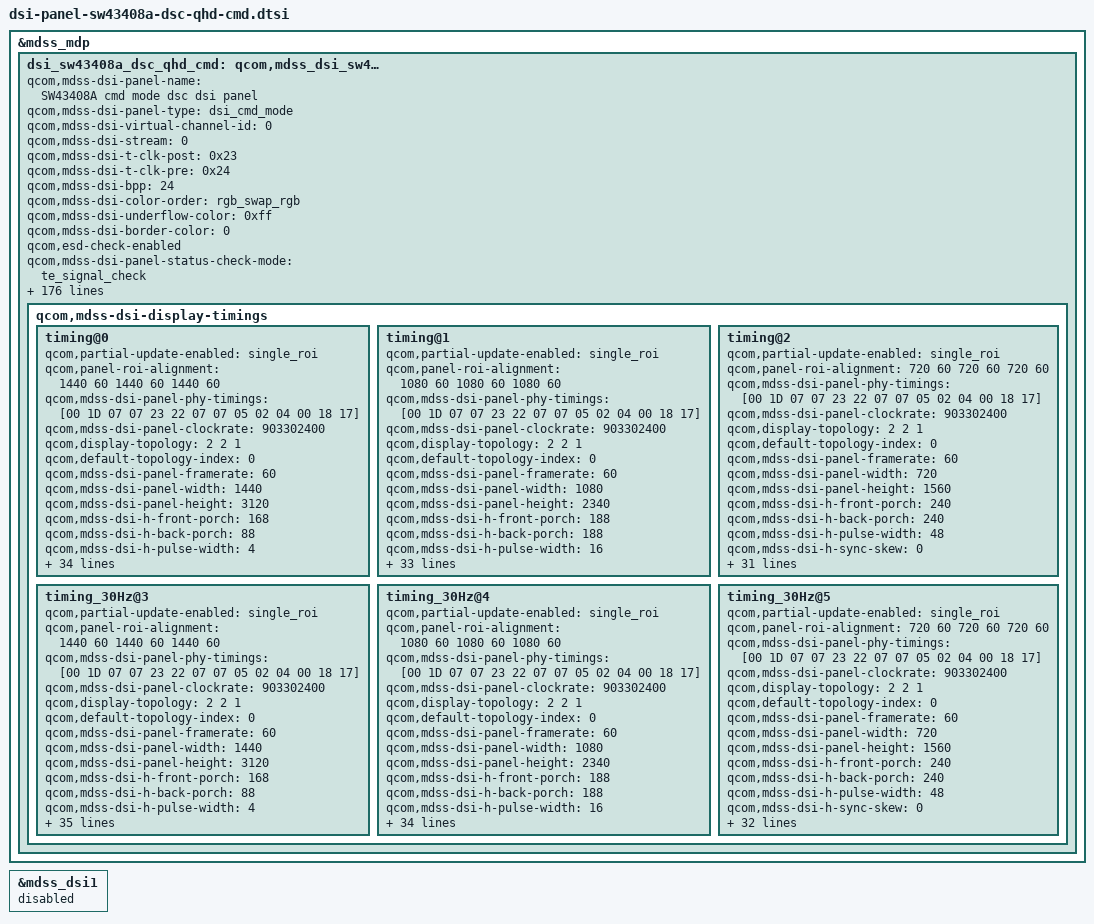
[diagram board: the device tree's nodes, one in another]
/* Copyright (c) 2014, Code Aurora Forum. All rights reserved.
 *
 * This program is free software; you can redistribute it and/or modify
 * it under the terms of the GNU General Public License version 2 and
 * only version 2 as published by the Free Software Foundation.
 *
 * This program is distributed in the hope that it will be useful,
 * but WITHOUT ANY WARRANTY; without even the implied warranty of
 * MERCHANTABILITY or FITNESS FOR A PARTICULAR PURPOSE.  See the
 * GNU General Public License for more details.
 */

&mdss_mdp {
    dsi_sw43408a_dsc_qhd_cmd: qcom,mdss_dsi_sw43408a_dsc_qhd_cmd {
        qcom,mdss-dsi-panel-name = "SW43408A cmd mode dsc dsi panel";
		qcom,mdss-dsi-panel-type = "dsi_cmd_mode";

		qcom,mdss-dsi-virtual-channel-id = <0>;
		qcom,mdss-dsi-stream = <0>;
		qcom,mdss-dsi-t-clk-post = <0x23>;
		qcom,mdss-dsi-t-clk-pre = <0x24>;
		qcom,mdss-dsi-bpp = <24>;
		qcom,mdss-dsi-color-order = "rgb_swap_rgb";
		qcom,mdss-dsi-underflow-color = <0xff>;
		qcom,mdss-dsi-border-color = <0>;
		qcom,esd-check-enabled;
		qcom,mdss-dsi-panel-status-check-mode = "te_signal_check";
		qcom,mdss-dsi-traffic-mode = "burst_mode";
		qcom,mdss-dsi-lane-map = "lane_map_0123";
		qcom,mdss-dsi-bllp-eof-power-mode;
		qcom,mdss-dsi-bllp-power-mode;
		qcom,mdss-dsi-lane-0-state;
		qcom,mdss-dsi-lane-1-state;
		qcom,mdss-dsi-lane-2-state;
		qcom,mdss-dsi-lane-3-state;
		qcom,mdss-dsi-reset-sequence = <1 10>, <0 2>, <1 10>;
		qcom,mdss-dsi-dma-trigger = "trigger_sw";
		qcom,mdss-dsi-mdp-trigger = "none";
		qcom,mdss-dsi-te-pin-select = <1>;
		qcom,mdss-dsi-wr-mem-start = <0x2c>;
		qcom,mdss-dsi-wr-mem-continue = <0x3c>;
		qcom,mdss-dsi-te-dcs-command = <1>;
		qcom,mdss-dsi-te-check-enable;
		qcom,mdss-dsi-te-using-te-pin;
		qcom,mdss-dsi-lp11-init;
		qcom,mdss-dsi-tx-eot-append;
		qcom,ulps-enabled;
		//qcom,mdss-dsi-force-clock-lane-hs = <1>;

		qcom,mdss-dsi-panel-hdr-enabled;
		qcom,mdss-dsi-panel-hdr-color-primaries = <14649 15851 33084 15473 13806 31961 7476 2719>;
		qcom,mdss-dsi-panel-peak-brightness = <5643000>;		/* max. 500nits */
		qcom,mdss-dsi-panel-blackness-level = <6134>;
		qcom,dynamic-mode-switch-enabled;
		qcom,dynamic-mode-switch-type = "dynamic-resolution-switch-immediate";
		lge,drs-mngr-enabled;
		lge,drs-mngr-internal-pps-switch-enabled;
		lge,use-ambient;
		lge,aod-interface-data = "partial", "partial", "partial";

		lge,blmap = <
			0
			1 1 2 3 4 4 5 6 6 7 7 7 7 8 8 9 10 10 11 13
			14 15 16 18 19 21 23 24 26 29 31 33 34 36 38 41 43 45 47 49
			52 54 56 58 60 63 67 71 75 79 84 88 92 97 101 106 111 115 120 123
			126 129 132 135 139 142 145 148 151 154 157 161 164 168 172 176 179 182 186 189
			193 197 201 206 209 212 216 219 222 226 229 232 235 238 241 245 248 252 255 258
			262 266 269 273 276 280 284 288 291 295 299 304 308 312 317 321 326 330 335 339
			344 348 353 358 362 367 372 377 382 388 394 400 405 410 415 420 426 431 436 441
			447 452 458 464 469 475 481 487 493 499 505 511 517 524 530 536 543 549 556 561
			566 570 575 581 586 592 597 603 608 614 619 625 630 636 641 647 653 658 663 668
			673 678 684 689 694 700 705 711 716 722 727 733 738 743 749 754 760 766 771 777
			782 787 792 797 803 808 814 820 826 831 834 837 840 843 846 849 851 854 857 860
			863 866 868 871 874 877 880 883 886 889 891 894 897 900 903 906 909 911 914 917
			920 923 926 929 932 935 938 941 944 947 951 954 957 960 964 964 964 964 964 964
			964 964 964 965 965 965 965 965 966 966 966 967 967 967 968 968 969 969 970 970
			971 972 972 973 974 974 975 977 978 979 980 982 983 985 986 987 989 991 992 993
			993 993 993 993 994 994 994 994 994 995 995 995 995 996 996 996 996 997 997 997
			997 998 998 998 999 999 999 999 1000 1000 1000 1001 1001 1001 1002 1002 1002 1003 1003 1004
			1004 1004 1005 1005 1006 1006 1006 1007 1007 1008 1008 1008 1009 1009 1010 1010 1011 1011 1012 1012
			1013 1013 1014 1014 1015
		>;
		lge,blmap-ve = <
			0
			9 9 9 9 9 9 9 9 9 9 10 12 13 15 16 18 19 20 22 23
			25 26 28 29 30 32 33 35 36 37 39 40 42 43 45 46 50 54 58 61
			65 69 73 77 81 84 88 92 96 100 104 107 111 115 119 123 127 130 134 138
			142 146 150 154 158 162 166 170 174 178 182 186 190 193 197 201 205 209 213 217
			221 226 231 236 237 242 247 251 256 261 266 270 275 280 285 290 294 299 304 309
			314 318 323 328 333 337 342 347 353 358 364 370 376 381 387 393 399 404 410 416
			422 427 433 439 444 450 456 462 467 473 479 485 490 496 502 509 515 521 528 534
			541 546 553 559 565 572 578 584 591 597 603 610 616 623 629 635 642 648 655 661
			667 674 680 686 692 698 705 711 717 723 730 736 742 748 754 761 767 773 779 785
			792 798 804 808 812 816 820 824 828 831 835 839 843 847 851 855 859 863 867 871
			874 878 882 886 890 894 898 902 905 909 913 917 920 924 928 931 935 939 943 946
			950 954 958 961 965 969 972 976 980 984 987 991 992 993 993 994 995 996 996 997
			998 999 1000 1000 1001 1002 1003 1004 1004 1005 1006 1007 1007 1008 1009 1009 1009 1009 1009 1009
			1009 1009 1009 1009 1009 1009 1009 1009 1009 1009 1009 1009 1009 1009 1009 1009 1009 1009 1009 1009
			1009 1009 1009 1009 1009 1009 1009 1009 1009 1009 1009 1009 1009 1009 1009 1009 1009 1010 1010 1010
			1010 1010 1010 1010 1010 1010 1010 1010 1010 1010 1011 1011 1011 1011 1011 1011 1011 1011 1011 1011
			1011 1011 1011 1011 1011 1011 1011 1011 1011 1011 1011 1011 1011 1011 1011 1011 1011 1011 1011 1012
			1012 1012 1012 1012 1012 1012 1012 1012 1012 1013 1013 1013 1013 1013 1013 1014 1014 1014 1014 1014
			1014 1015 1015 1015 1015
		>;
		lge,blmap-ex = <
			1
			131 131 131 131 131 131 131 131 131 147 160 175 186 196 208 218 227 234 242 251
			258 264 270 277 284 289 295 300 306 311 317 322 327 332 335 338 350 361 373 384
			393 402 410 418 426 434 442 449 456 462 468 474 480 486 492 498 503 508 513 517
			522 527 532 536 541 545 549 553 557 561 565 569 572 576 580 585 590 595 599 603
			607 612 616 620 624 629 633 637 643 648 654 658 662 667 671 675 679 682 685 688
			691 694 696 699 702 705 708 712 715 718 724 730 736 741 746 752 758 764 774 785
			790 796 801 807 813 819 826 832 838 843 848 854 859 865 865 865 865 865 865 865
			875 883 890 898 905 913 923 931 938 945 953 961 970 978 985 993 999 1006 1012 1012
			1012 1012 1012 1012 1012 1012 1012 1012 1012 1012 1012 1012 1012 1012 1012 1012 1012 1012 1012 1012
			1012 1012 1012 1012 1012 1012 1012 1012 1012 1012 1012 1012 1012 1012 1012 1012 1012 1012 1012 1012
			1012 1012 1012 1012 1012 1012 1012 1012 1012 1012 1012 1012 1012 1012 1012 1012 1012 1012 1012 1012
			1012 1012 1012 1012 1012 1012 1012 1012 1012 1012 1012 1012 1012 1012 1012 1012 1012 1012 1012 1012
			1012 1012 1012 1012 1012 1012 1012 1012 1012 1012 1012 1012 1012 1012 1012
		>;

		lge,dynamic-blmap-normal = <
			0
			7 7 7 7 7 7 7 7 7 7 8 9 10 11 12 13 13 14 15 16
			17 18 19 20 21 22 23 24 25 25 26 27 28 29 30 31 33 36 38 40
			42 45 47 49 52 54 56 58 61 63 65 67 70 72 74 77 79 81 83 86
			88 91 94 98 101 104 107 110 114 117 120 123 127 130 133 136 139 143 146 149
			152 155 159 162 165 168 171 175 178 181 184 188 191 194 197 200 204 207 210 213
			216 220 223 226 229 233 236 239 242 245 248 251 254 257 260 263 266 269 272 275
			278 281 284 287 290 293 296 299 302 305 308 311 314 317 321 325 329 334 338 342
			346 349 353 357 362 366 370 374 378 382 387 391 395 399 403 407 412 416 421 426
			431 436 442 447 452 457 462 467 472 477 483 488 493 498 503 508 513 518 524 529
			534 539 544 549 554 558 563 568 573 578 582 587 592 597 602 606 611 616 621 625
			630 635 640 645 649 654 659 664 668 673 677 682 686 691 695 700 705 709 714 718
			723 727 732 737 741 746 750 755 759 764 768 773 777 781 784 788 792 796 800 804
			807 811 815 819 823 827 830 834 838 842 846 850 853 857 861 864 868 871 875 878
			881 885 888 891 895 898 902 905 908 912 915 919 922 925 929 932 936 939 942 946
			949 952 956 959 963 966 967 968 969 971 972 973 974 975 977 980 982 984 986 989
			991 993 993 993 994 994 994 994 994 994 995 995 995 995 995 995 995 996 996 996
			996 997 997 998 998 998 999 999 999 1000 1000 1001 1001 1001 1002 1002 1003 1003 1004 1004
			1005 1005 1006 1006 1007 1007 1007 1008 1008 1009 1009 1010 1010 1010 1011 1011 1012 1012 1012 1013
			1013 1014 1014 1015 1015
		>;
		lge,dynamic-blmap-brighter = <
			0
			7 7 7 7 7 7 7 7 7 7 7 7 7 8 8 9 10 10 11 13
			14 15 16 18 19 21 23 24 26 29 31 33 34 36 38 41 43 45 47 49
			52 54 56 58 60 63 67 71 75 79 84 88 92 97 101 106 111 115 120 123
			126 129 132 135 139 142 145 148 151 154 157 161 164 168 172 176 179 182 186 189
			193 197 201 206 209 212 216 219 222 226 229 232 235 238 241 245 248 252 255 258
			262 266 269 273 276 280 284 288 291 295 299 304 308 312 317 321 326 330 335 339
			344 348 353 358 362 367 372 377 382 388 394 400 405 410 415 420 426 431 436 441
			447 452 458 464 469 475 481 487 493 499 505 511 517 524 530 536 543 549 556 561
			566 570 575 581 586 592 597 603 608 614 619 625 630 636 641 647 653 658 663 668
			673 678 684 689 694 700 705 711 716 722 727 733 738 743 749 754 760 766 771 777
			782 787 792 797 803 808 814 820 826 831 834 837 840 843 846 849 851 854 857 860
			863 866 868 871 874 877 880 883 886 889 891 894 897 900 903 906 909 911 914 917
			920 923 926 929 932 935 938 941 944 947 951 954 957 960 964 964 964 964 964 964
			964 964 964 965 965 965 965 965 966 966 966 967 967 967 968 968 969 969 970 970
			971 972 972 973 974 974 975 977 978 979 980 982 983 985 986 987 989 991 992 993
			993 993 993 993 994 994 994 994 994 995 995 995 995 996 996 996 996 997 997 997
			997 998 998 998 999 999 999 999 1000 1000 1000 1001 1001 1001 1002 1002 1002 1003 1003 1004
			1004 1004 1005 1005 1006 1006 1006 1007 1007 1008 1008 1008 1009 1009 1010 1010 1011 1011 1012 1012
			1013 1013 1014 1014 1015
		>;
		lge,blmap-hdr = <
			0
			7 7 7 7 7 7 7 7 7 7 8 10 11 12 14 15 16 18 19 20
			22 23 25 26 27 29 30 31 33 34 35 37 38 39 41 42 46 49 53 56
			60 64 67 71 74 78 82 85 89 92 96 100 103 107 110 114 118 121 125 128
			132 136 140 144 147 151 155 159 163 167 170 174 178 182 186 190 193 197 201 205
			209 213 217 221 224 228 233 237 241 245 250 254 258 262 267 271 275 279 284 288
			292 296 301 305 309 313 318 322 327 332 337 343 348 353 358 363 368 374 379 384
			389 394 399 404 410 415 420 425 430 435 441 446 451 456 462 468 474 480 487 493
			499 504 510 516 522 528 535 541 547 553 559 565 571 577 584 590 596 602 609 615
			621 627 633 639 645 651 657 663 669 675 681 687 693 699 705 711 717 723 729 735
			741 747 753 758 762 767 772 777 781 786 791 795 800 805 810 814 819 824 828 833
			838 842 847 852 857 861 866 869 872 875 878 882 885 888 891 894 897 900 903 907
			910 913 916 919 922 925 928 932 935 938 941 944 947 949 952 954 957 959 962 964
			967 969 972 974 977 979 982 984 987 989 992 994 997 999 1002 1002 1002 1002 1002 1002
			1002 1002 1002 1002 1002 1002 1002 1002 1002 1002 1003 1003 1003 1003 1003 1003 1003 1003 1003 1003
			1003 1003 1003 1003 1003 1003 1003 1003 1003 1004 1004 1004 1004 1004 1004 1004 1004 1005 1005 1005
			1005 1005 1005 1005 1005 1005 1005 1005 1005 1005 1006 1006 1006 1006 1006 1006 1006 1006 1006 1006
			1006 1006 1006 1007 1007 1007 1007 1007 1007 1008 1008 1008 1008 1008 1008 1008 1009 1009 1009 1009
			1009 1009 1010 1010 1010 1010 1010 1011 1011 1011 1011 1012 1012 1012 1012 1013 1013 1013 1013 1014
			1014 1014 1014 1015 1015
		>;

		qcom,mdss-pan-physical-width-dimension = <68>;
		qcom,mdss-pan-physical-height-dimension = <147>;

		lge,update-pps-in-lp-mode;
		lge,mdss-dsi-nolp-command = [
			15 01 00 00 00 00 02 B0 AC
			39 01 00 00 00 00 05 30 00 00 0C 2F
			39 01 00 00 00 00 05 31 00 00 05 9F
			39 01 00 00 00 00 07 55 16 29 C0 04 78 DB
			39 01 00 00 00 00 0B C3 10 15 1F 12 AD 4D B1 51 BD 1D
			39 01 00 00 00 00 08 E5 00 3A 00 36 00 3A 10
			39 01 00 00 00 00 3D E6 0F FF 00 0F FF 00 0F FF 00 0F FF 00 0F FF 00 0F FF 00 0F FF 00 0F FF 00 0F FF 00 0F FF 00 0F FF 00 0F FF 00 0F FF 00 0F FF 00 0F FF 00 0F FF 00 0F FF 00 0F FF 00 0F FF 00 0F FF 00
			39 01 00 00 00 00 1F E7 0F FF 00 0F FF 00 0F FF 00 0F FF 00 0F FF 00 0F FF 00 0F FF 00 0F FF 00 0F FF 00 0F FF 00
			15 01 00 00 00 00 02 EA 6F
			39 01 00 00 28 00 0F CB 80 5C 07 11 34 54 4F 5A 33 19 60 00 00 00
			05 01 00 00 00 00 01 13
			39 01 00 00 55 00 0D B4 2F 02 11 03 31 31 31 0A 10 92 12 00
			39 01 00 00 00 00 08 E5 00 3A 00 36 00 0F 10
			39 01 00 00 00 00 3D E6 30 00 12 30 00 12 30 00 12 30 00 12 11 B0 61 02 4D C4 02 B3 5E 02 DB 37 02 EA 27 0F FF 00 30 00 12 30 00 12 30 00 12 30 00 12 11 B0 61 02 4D C4 02 B3 5E 02 DB 37 02 EA 27 0F FF 00
			39 01 00 00 00 00 1F E7 30 00 13 30 00 13 30 00 13 38 94 AD 38 94 AD 30 00 13 30 00 13 30 00 13 38 94 AD 38 94 AD
			15 01 00 00 00 00 02 B0 CA
		];
		lge,mdss-dsi-nolp-command-state = "dsi_lp_mode";

		lge,mdss-dsi-aod-area-command = [
			15 01 00 00 00 00 02 B0 AC
			39 01 00 00 00 00 05 30 00 00 02 CF
			39 01 00 00 00 00 05 31 00 00 05 9F
		];
		lge,mdss-dsi-aod-area-command-state = "dsi_lp_mode";

		lge,mdss-dsi-lp2-command = [
			15 01 00 00 00 00 02 B0 AC
			39 01 00 00 00 00 07 55 16 29 C9 04 78 DB
			39 01 00 00 00 00 19 C2 70 8A 0A 0A 33 8C 8C 33 8C 8C 0A ED AD 63 23 00 00 64 24 43 60 15 15 64
			39 01 00 00 00 00 0B C3 10 15 1F 12 AD 4D B1 51 BD 1D
			39 01 00 00 00 00 08 E5 00 3A 00 36 00 3A 10
			39 01 00 00 00 00 3D E6 0F FF 00 0F FF 00 0F FF 00 0F FF 00 0F FF 00 0F FF 00 0F FF 00 0F FF 00 0F FF 00 0F FF 00 0F FF 00 0F FF 00 0F FF 00 0F FF 00 0F FF 00 0F FF 00 0F FF 00 0F FF 00 0F FF 00 0F FF 00
			39 01 00 00 00 00 1F E7 0F FF 00 0F FF 00 0F FF 00 0F FF 00 0F FF 00 0F FF 00 0F FF 00 0F FF 00 0F FF 00 0F FF 00
			15 01 00 00 00 00 02 EA EF
			39 01 00 00 00 00 0D B4 2F 00 11 03 31 31 31 0A 10 92 12 00
			39 01 00 00 00 00 13 BF 30 F6 11 33 00 00 00 00 00 00 00 00 00 00 33 01 00 20
			39 01 00 00 00 00 03 C1 01 48
			39 01 00 00 00 00 05 CA 08 99 10 0F
			39 01 00 00 00 00 0F CB 80 5C 07 07 34 54 4F 5A 33 19 60 00 00 00
			05 01 00 00 46 00 01 34
			39 01 00 00 00 00 03 51 00 10
			05 01 00 00 00 00 01 12
			05 01 00 00 55 00 01 35
			39 01 00 00 00 00 08 E5 00 3A 00 36 00 0F 10
			39 01 00 00 00 00 3D E6 30 00 12 30 00 12 30 00 12 30 00 12 11 3A D7 11 89 89 11 D7 3A 02 26 EC 02 C3 4F 0F FF 00 30 00 12 30 00 12 30 00 12 30 00 12 11 3A D7 11 89 89 11 D7 3A 02 26 EC 02 C3 4F 0F FF 00
			39 01 00 00 14 00 1F E7 30 00 13 30 00 13 30 00 13 38 94 AD 38 94 AD 30 00 13 30 00 13 30 00 13 38 94 AD 38 94 AD
			39 01 00 00 00 00 19 C2 70 8A 0A 0A 33 8C 8C 33 8C 8C 0A ED AD 63 23 00 00 64 24 43 64 15 15 64
			15 01 00 00 00 00 02 B0 CA
		];
		lge,mdss-dsi-lp2-command-state = "dsi_lp_mode";

		lge,use-vr-lp-mode;
		lge,mdss-dsi-vr-lp-mode-on-command = [
			15 01 00 00 00 00 02 B0 AC
			05 01 00 00 14 00 01 28
			39 01 00 00 00 00 07 55 04 78 DB 04 78 DB
			39 01 00 00 14 00 03 53 2C 30
			39 01 00 00 00 00 08 E5 00 3A 00 36 00 0F 30
			39 01 00 00 14 00 2A B5 75 60 2D 5D 80 00 0A 0B 00 05 0B 00 80 17 27 85 EE 0C 00 16 50 AA CC 80 17 27 37 EE 4C 00 16 30 3F 00 81 00 03 1F 1F 03 03
			05 01 00 00 00 00 01 29
			15 01 00 00 00 00 02 B0 CA
		];
		lge,mdss-dsi-vr-pre-lp-mode-off-command = [
			15 01 00 00 00 00 02 B0 AC
			05 01 00 00 14 00 01 28
			39 01 00 00 14 00 2A B5 75 60 2D 5D 80 00 0A 0B 00 05 0B 00 80 17 27 85 EE 0C 00 16 50 AA CC 80 17 27 37 EE 4C 00 16 30 3F 00 81 00 03 03 00 01 00
			39 01 00 00 14 00 08 E5 00 3A 00 36 00 0F 10
		];
		lge,mdss-dsi-vr-post-lp-mode-off-command = [
			05 01 00 00 00 00 01 29
			15 01 00 00 00 00 02 B0 CA
		];
		lge,mdss-dsi-vr-lp-command-state = "dsi_lp_mode";
		lge,blmap-vr = < 0 1023 >;

		lge,ddic-bist-enabled;
		lge,ddic-bist-usage-type = "rsvd", "rsvd", "rsvd", "rsvd", "rsvd";
		lge,mdss-dsi-bist-on-command = [
			39 01 00 00 21 00 09 FA 03 01 3F FF 00 00 13 01
		];
		lge,mdss-dsi-bist-off-command = [
			39 01 00 00 00 00 09 FA 00 00 3F FF 00 00 13 01
		];

		lge,use-panel-err-detect;
		interrupt-parent = <&tlmm>;
		interrupts = <7 0x2001>; /*IRQF_ONESHOT | IRQF_TRIGGER_RISING*/
		lge,err-detect-gpio = <&tlmm 7 0x2001>; /* IRQF_ONESHOT | IRQF_TRIGGER_RISING */

		lge,memory-error-detect-command = [
			39 01 00 00 00 00 05 CE 22 10 00 00
		];
		lge,memory-error-detect-command-state = "dsi_hs_mode";

		lge,esd-detect-command = [
			39 01 00 00 00 00 05 CE 22 1E 00 00
			39 01 00 00 00 00 04 C5 88 08 00
		];
		lge,esd-detect-command-state = "dsi_hs_mode";
		lge,line-defect-detect-command = [
			39 01 00 00 00 00 05 CE 00 16 00 00
		];
		lge,line-defect-detect-command-state = "dsi_hs_mode";

		lge,use-line-detect;
		lge,detect-vert-line-restore-command = [
			15 01 00 00 00 00 02 B0 AC
			39 01 00 00 00 00 19 C2 70 8A 0A 0A 33 8C 8C 33 8C 8C 0A ED AD 63 23 00 00 64 24 43 64 15 15 64
			39 01 00 00 00 00 12 C3 10 15 1F 12 AD 4D B1 51 BD 1D 22 02 C8 20 83 0C 17
			15 01 00 00 00 00 02 B0 CA
		];
		lge,detect-vert-line-restore-command-state = "dsi_hs_mode";
		lge,detect-black-vert-line-command = [
			15 01 00 00 00 00 02 B0 AC
			39 01 00 00 00 00 19 C2 70 93 0A 0A 33 96 8C 33 8C 8C 0A ED AD 63 23 00 00 64 24 43 64 15 15 64
			39 01 00 00 00 00 12 C3 10 15 15 12 AD 4D BF 51 BD 1D 22 02 C8 20 83 0C 17
			15 01 00 00 00 00 02 B0 CA
		];
		lge,detect-black-vert-line-command-state = "dsi_hs_mode";
		lge,detect-white-vert-line-command = [
			15 01 00 00 00 00 02 B0 AC
			39 01 00 00 00 00 19 C2 70 80 0A 0A 33 82 8C 33 8C 8C 0A ED AD 63 23 00 00 64 24 43 64 15 15 64
			39 01 00 00 00 00 12 C3 10 15 15 12 AD 4D BF 51 BD 1D 22 02 C8 20 83 0C 17
			15 01 00 00 00 00 02 B0 CA
		];
		lge,detect-white-vert-line-command-state = "dsi_hs_mode";
		lge,use-ddic-register-lock;
		lge,ddic-register-lock = [
			15 01 00 00 10 00 02 B0 CA
		];

		lge,ddic-register-unlock = [
			39 01 00 00 10 00 02 B0 AC
		];
		lge,ddic-register-lock-unlock-state = "dsi_lp_mode";

		lge,use-bc-dim;
		lge,bc-dimming-work;
		lge,mdss-dsi-bc-default-command = [
			15 00 00 00 00 00 02 B0 AC
			39 00 00 00 00 00 19 D0 D2 21 23 1f 21 41 00 00 00 52 41 00 00 00 08 00 C4 8F 8F 98 96 01 00 00
			15 01 00 00 00 00 02 B0 CA
		];
		lge,mdss-dsi-bc-default-command-state = "dsi_hs_mode";

		lge,use-color-manager;
		lge,color-manager-default-status = <1>;
		lge,mdss-dsi-color-manager-mode-table = <3 1>, <0 1>, <2 1>, <1 1>;
		lge,true-view-supported;

		lge,mdss-dsi-disp-ctrl-command-1 = [
			39 01 00 00 00 00 03 53 4c 30
		];
		lge,mdss-dsi-disp-ctrl-command-1-state = "dsi_hs_mode";
		lge,mdss-dsi-disp-ctrl-command-2 = [
			39 01 00 00 00 00 04 55 16 29 C0
		];
		lge,mdss-dsi-disp-ctrl-command-2-state = "dsi_hs_mode";

		lge,digital-gamma-set = [
			39 01 00 00 00 00 21 EC 3F 03 05 AF 03 01 6B 03 01 6B 00 FF 80 00 80 00 80 00 80 00 EE 7E FC 7A F7 75 F3 71 00 C0 78 F0
			39 01 00 00 00 00 06 ED 68 E0 59 D1 49
			39 01 00 00 00 00 21 EC 3F 03 01 6B 03 01 6B 03 05 AF 00 E8 7D FA 77 F4 72 EF 6C 00 EE 7E FC 7A F7 75 F3 71 00 FF 80 00
			39 01 00 00 00 00 06 ED 80 00 80 00 80
			39 01 00 00 00 00 21 EC 3F 03 01 6B 03 01 6B 03 05 AF 00 EB 7D FB 78 F6 73 F1 6E 00 F0 7E FC 7A F8 77 F5 73 00 FF 80 00
			39 01 00 00 00 00 06 ED 80 00 80 00 80
			39 01 00 00 00 00 21 EC 3F 03 01 6B 03 01 6B 03 05 AF 00 EF 7E FC 7A F8 76 F4 72 00 F2 7E FD 7B F9 78 F6 75 00 FF 80 00
			39 01 00 00 00 00 06 ED 80 00 80 00 80
			39 01 00 00 00 00 21 EC 3F 03 01 6B 03 01 6B 03 05 AF 00 F3 7E FD 7B FA 78 F7 75 00 F5 7F FD 7C FB 7A F8 77 00 FF 80 00
			39 01 00 00 00 00 06 ED 80 00 80 00 80
			39 01 00 00 00 00 21 EC 3F 03 01 6B 03 01 6B 03 05 AF 00 F9 7F FE 7E FD 7C FB 7B 00 FA 7F FF 7E FD 7D FC 7C 00 FF 80 00
			39 01 00 00 00 00 06 ED 80 00 80 00 80
			39 01 00 00 00 00 21 EC 3F 03 05 AF 03 05 AF 03 05 AF 00 FF 80 00 80 00 80 00 80 00 FF 80 00 80 00 80 00 80 00 FF 80 00
			39 01 00 00 00 00 06 ED 80 00 80 00 80
			39 01 00 00 00 00 21 EC 3F 03 05 AF 03 05 6B 03 01 6B 00 FF 80 00 80 00 80 00 80 00 FE 80 00 80 FF 7F FF 7F 00 FC 80 FF
			39 01 00 00 00 00 06 ED 7F FE 7E FE 7D
			39 01 00 00 00 00 21 EC 3F 03 05 AF 03 01 6B 03 01 6B 00 FF 80 00 80 00 80 00 80 00 FD 80 FF 7F FF 7F FE 7E 00 F8 7F FE
			39 01 00 00 00 00 06 ED 7D FC 7C FB 7A
			39 01 00 00 00 00 21 EC 3F 03 05 AF 03 01 6B 03 01 6B 00 FF 80 00 80 00 80 00 80 00 FB 7F FF 7E FE 7D FD 7C 00 F3 7E FD
			39 01 00 00 00 00 06 ED 7B FA 78 F7 75
			39 01 00 00 00 00 21 EC 3F 03 05 AF 03 01 6B 03 01 6B 00 FF 80 00 80 00 80 00 80 00 FA 7F FF 7E FD 7D FC 7C 00 EF 7E FC
			39 01 00 00 00 00 06 ED 7A F8 76 F4 72
			39 01 00 00 00 00 21 EC 3F 03 05 AF 03 01 6B 03 01 6B 00 FF 80 00 80 00 80 00 80 00 F9 7F FE 7E FD 7C FB 7B 00 EB 7D FB
			39 01 00 00 00 00 06 ED 78 F6 73 F1 6E
			39 01 00 00 00 00 21 EC 3F 03 05 AF 03 01 6B 03 01 6B 00 FF 80 00 80 00 80 00 80 00 F7 7F FE 7D FC 7B FA 79 00 E7 7D FA
			39 01 00 00 00 00 06 ED 77 F4 71 EE 6B
			39 01 00 00 00 00 21 EC 3F 03 05 AF 03 01 6B 03 01 6B 00 FF 80 00 80 00 80 00 80 00 F5 7F FD 7C FB 7A F8 77 00 E2 7C F9
			39 01 00 00 00 00 06 ED 75 F1 6E EA 67
			39 01 00 00 00 00 21 EC 3F 03 05 AF 03 01 6B 03 01 6B 00 FF 80 00 80 00 80 00 80 00 F1 7E FC 7B F9 77 F5 74 00 DB 7B F7
			39 01 00 00 00 00 06 ED 72 EE 69 E5 60
			39 01 00 00 00 00 21 EC 3F 03 05 AF 03 01 6B 03 01 6B 00 FF 80 00 80 00 80 00 80 00 EF 7E FC 7A F8 76 F4 72 00 D5 7B F5
			39 01 00 00 00 00 06 ED 70 EB 66 E0 5B
			39 01 00 00 00 00 21 EC 3F 03 05 AF 03 01 6B 03 01 6B 00 FF 80 00 80 00 80 00 80 00 EC 7E FB 79 F6 74 F2 6F 00 CE 7A F4
			39 01 00 00 00 00 06 ED 6E E7 61 DB 55
			39 01 00 00 00 00 21 EC 3F 03 05 AF 03 01 6B 03 01 6B 00 FF 80 00 80 00 80 00 80 00 EA 7D FB 78 F5 73 F0 6E 00 C8 79 F2
			39 01 00 00 00 00 06 ED 6B E4 5E D7 50
			39 01 00 00 00 00 21 EC 3F 03 05 AF 03 01 6B 03 01 6B 00 FF 80 00 80 00 80 00 80 00 E7 7D FA 77 F4 71 EE 6B 00 C2 78 F1
			39 01 00 00 00 00 06 ED 69 E1 5A D2 4B
			39 01 00 00 00 00 21 EC 3F 03 05 AF 03 01 6B 03 01 6B 00 FF 80 00 80 00 80 00 80 00 E5 7D F9 76 F3 70 EC 69 00 BD 78 EF
			39 01 00 00 00 00 06 ED 67 DF 57 CE 46
			39 01 00 00 00 00 21 EC 3F 03 05 AF 03 01 6B 03 01 6B 00 FF 80 00 80 00 80 00 80 00 E3 7C F9 75 F2 6E EB 67 00 B8 77 EE
			39 01 00 00 00 00 06 ED 65 DC 54 CB 42
			39 01 00 00 00 00 21 EC 3F 03 05 AF 03 01 6B 03 01 6B 00 FF 80 00 80 00 80 00 80 00 E2 7C F9 75 F1 6E EA 67 00 B3 76 ED
			39 01 00 00 00 00 06 ED 63 DA 50 C7 3D
			39 01 00 00 00 00 21 EC 3F 03 05 AF 03 01 6B 03 01 6B 00 FF 80 00 80 00 80 00 80 00 DF 7C F8 74 F0 6C E8 64 00 AD 76 EB
			39 01 00 00 00 00 06 ED 61 D7 4D C2 38
			39 01 00 00 00 00 21 EC 3F 03 05 AF 03 01 6B 03 01 6B 00 FF 80 00 80 00 80 00 80 00 DD 7C F7 73 EF 6B E6 62 00 A8 75 EA
			39 01 00 00 00 00 06 ED 5F D4 4A BF 34
			39 01 00 00 00 00 21 EC 3F 03 05 AF 03 01 6B 03 01 6B 00 FF 80 00 80 00 80 00 80 00 DB 7B F7 72 EE 69 E5 60 00 A4 75 E9
			39 01 00 00 00 00 06 ED 5E D2 47 BC 30
			39 01 00 00 00 00 21 EC 3F 03 05 AF 03 01 6B 03 01 6B 00 FF 80 00 80 00 80 00 80 00 D9 7B F6 72 ED 68 E3 5F 00 9F 74 E8
			39 01 00 00 00 00 06 ED 5C D0 44 B8 2C
			39 01 00 00 00 00 21 EC 3F 03 01 6B 03 01 6B 03 01 6B 00 FD 80 FF 7F FF 7F FE 7E 00 D4 7B F5 70 EA 65 E0 5A 00 98 73 E6
			39 01 00 00 00 00 06 ED 59 CC 40 B3 26
		];
		lge,digital-gamma-command-state = "dsi_hs_mode";

		lge,mdss-dsi-ve-on-command = [
			15 00 00 00 00 00 02 B0 55
			39 00 00 00 00 00 0A C1 C3 05 00 C3 05 00 C3 05 00
			15 01 00 00 00 00 02 B0 CA
		];
		lge,mdss-dsi-ve-on-command-state = "dsi_hs_mode";

		lge,mdss-dsi-ve-off-command = [
			15 00 00 00 00 00 02 B0 55
			39 00 00 00 00 00 0A C1 FF 07 00 FF 07 00 FF 07 00
			15 01 00 00 00 00 02 B0 CA
		];
		lge,mdss-dsi-ve-off-command-state = "dsi_hs_mode";

		lge,mdss-dsi-wb-default-command = [
			15 00 00 00 00 00 02 B0 55
			39 00 00 00 00 00 21 EC 3F 03 05 AF 03 01 6B 03 01 6B 00 FF 80 00 80 00 80 00 80 00 ED 7E FB 79 F7 75 F2 70 00 CA 79 F3
			39 00 00 00 00 00 06 ED 6C E5 5F D8 52
			15 01 00 00 00 00 02 B0 CA
		];
		lge,mdss-dsi-wb-default-command-state = "dsi_hs_mode";

		lge,digital-gamma-cmds-dummy = [
			15 00 00 00 00 00 02 B0 55
			39 00 00 00 00 00 21 EC 3F 03 05 AF 03 01 6B 03 01 6B 00 FF 80 00 80 00 80 00 80 00 ED 7E FB 79 F7 75 F2 70 00 CA 79 F3
			39 00 00 00 00 00 06 ED 6C E5 5F D8 52
			15 01 00 00 00 00 02 B0 CA
		];
		lge,digital-gamma-cmds-dummy-command = "dsi_hs_mode";

		lge,mdss-dsi-saturation-command = [
			15 00 00 00 00 00 02 B0 55
			39 00 00 00 00 00 21 CC 88 0A 4B 6C FF 58 60 60 80 67 70 80 7A 74 6E 60 79 65 60 60 68 74 67 87 7A 74 6A 60 7A 7A 5C 6C
			39 00 00 00 00 00 21 CD 6C 80 80 7A 79 75 6A 68 7C 83 83 83 83 83 83 83 83 83 83 83 83 83 83 83 83 83 83 83 83 83 83 83
			15 01 00 00 00 00 02 B0 CA
		];
		lge,mdss-dsi-saturation-command-state = "dsi_hs_mode";

		lge,mdss-dsi-hue-command = [
			15 00 00 00 00 00 02 B0 55
			39 00 00 00 00 00 21 CE 83 83 83 83 83 83 83 7A 83 83 83 83 83 7F 7F 7F 7F 7F 7F 7F 7E 7E 7E 7F 7F F4 00 06 02 01 0A E4
			39 00 00 00 00 00 21 CF EF EF EF F6 06 00 0A 81 D3 FF 4C 50 48 48 4C 50 50 4A 45 4E 4C 52 54 54 54 58 58 68 65 6B 53 5B
			15 01 00 00 00 00 02 B0 CA
		];
		lge,mdss-dsi-hue-command-state = "dsi_hs_mode";

		lge,mdss-dsi-sharpness-command = [
			15 00 00 00 00 00 02 B0 55
			39 00 00 00 00 00 1F DD FB F8 40 10 07 06 04 04 20 06 30 20 03 80 04 01 02 58 E0 00 8F 00 FF 7F A0 00 E0 08 C0 10
			15 01 00 00 00 00 02 B0 CA
		];
		lge,mdss-dsi-sharpness-command-state = "dsi_hs_mode";

		lge,mdss-dsi-cm-sports = [
			15 00 00 00 00 00 02 B0 55
			39 00 00 00 00 00 21 EC 3F 03 01 6B 03 01 6B 03 05 AF 00 E3 7C F9 75 F2 6E EB 67 00 EC 7D FB 79 F6 74 F2 6F 00 FF 80 00
			39 00 00 00 00 00 06 ED 80 00 80 00 80
			15 01 00 00 00 00 02 B0 CA
		];
		lge,mdss-dsi-cm-sports-state = "dsi_hs_mode";

		lge,mdss-dsi-cm-game = [
			15 00 00 00 00 00 02 B0 55
			39 00 00 00 00 00 21 CC 88 0A 4B 6C FF 61 6A 6A 8D 71 7B 95 86 83 79 6A 85 6F 6A 6A 72 84 71 95 86 81 75 6A 86 7A 5C 6C
			39 00 00 00 00 00 21 CD 6C 80 80 80 7A 78 6A 68 7C 83 83 83 83 83 83 83 83 83 83 83 83 83 83 83 83 83 83 83 83 83 83 83
			39 00 00 00 00 00 21 EC 3F 03 01 6B 03 01 6B 03 05 AF 00 F5 7E FD 7C FB 7A F9 77 00 FB 7F FF 7E FE 7E FD 7D 00 FF 80 00
			39 00 00 00 00 00 06 ED 80 00 80 00 80
			15 01 00 00 00 00 02 B0 CA
		];
		lge,mdss-dsi-cm-game-state = "dsi_hs_mode";

		lge,mdss-dsi-hdr-set = [
			15 00 00 00 00 00 02 55 14
			15 00 00 00 00 00 02 B0 55
			15 00 00 00 00 00 02 E2 DC
			15 01 00 00 00 00 02 B0 CA
		];
		lge,mdss-dsi-hdr-set-state = "dsi_lp_mode";

		lge,use-irc-ctrl;
		lge,mdss-dsi-irc-command = [
			15 00 00 00 00 00 02 B0 55
			15 00 00 00 00 00 02 E2 FC
			15 01 00 00 00 00 02 B0 CA
		];
		lge,mdss-dsi-irc-command-state = "dsi_lp_mode";

		lge,use-ace-ctrl;
		lge,default-ace-mode = <3>;
		lge,mdss-dsi-ace-tune-command = [
			15 00 00 00 00 00 02 B0 55
			39 00 00 00 00 00 0A C1 C0 05 00 C0 05 00 C0 05 00
			39 00 00 00 00 00 21 C2 98 FF F9 F3 EE E8 E3 DD D8 D2 CD C7 C2 BC B7 B1 AC A6 A1 9B 96 90 8B 85 80 80 80 80 80 80 80 80
			15 01 00 00 00 00 02 B0 CA
		];
		lge,mdss-dsi-ace-restore-command = [
			15 00 00 00 00 00 02 B0 55
			39 00 00 00 00 00 0A C1 FF 07 00 FF 07 00 FF 07 00
			39 00 00 00 00 00 21 C2 B8 A6 A6 A6 A5 A4 A1 9F 9C 98 94 92 8F 8D 8A 88 85 84 83 82 81 81 80 80 80 80 80 80 80 80 80 80
			15 01 00 00 00 00 02 B0 CA
		];
		lge,mdss-dsi-ace-cmmand-state = "dsi_lp_mode";

		qcom,mdss-dsi-display-timings {
			timing@0{
				qcom,partial-update-enabled = "single_roi";
				qcom,panel-roi-alignment = <1440 60 1440 60 1440 60>;
				qcom,mdss-dsi-panel-phy-timings = [00 1D 07 07 23 22 07 07 05 02 04 00 18 17];
				qcom,mdss-dsi-panel-clockrate = <903302400>;
				qcom,display-topology = <2 2 1>;
				qcom,default-topology-index = <0>;
				qcom,mdss-dsi-panel-framerate = <60>;
				qcom,mdss-dsi-panel-width = <1440>;
				qcom,mdss-dsi-panel-height = <3120>;
				qcom,mdss-dsi-h-front-porch = <168>;
				qcom,mdss-dsi-h-back-porch = <88>;
				qcom,mdss-dsi-h-pulse-width = <4>;
				qcom,mdss-dsi-h-sync-skew = <0>;
				qcom,mdss-dsi-v-back-porch = <10>;
				qcom,mdss-dsi-v-front-porch = <9>;
				qcom,mdss-dsi-v-pulse-width = <1>;
				qcom,mdss-dsi-h-left-border = <0>;
				qcom,mdss-dsi-h-right-border = <0>;
				qcom,mdss-dsi-v-top-border = <0>;
				qcom,mdss-dsi-v-bottom-border = <0>;
				qcom,mdss-mdp-transfer-time-us = <15200>;

				qcom,mdss-dsi-on-command = [
					07 01 00 00 00 00 02 11 00
					15 01 00 00 00 00 02 B0 AC
					39 01 00 00 00 00 07 F7 01 49 0C FF 7F 04
					15 01 00 00 00 00 02 B0 CA
					39 01 00 00 00 00 07 55 00 70 DF 00 70 DF
					05 01 00 00 82 00 01 11
					15 01 00 00 00 00 02 26 02
					15 01 00 00 00 00 02 3D 08
					39 01 00 00 00 00 03 53 4C 30
					15 01 00 00 00 00 02 35 00
					39 01 00 00 00 00 03 44 00 00
					39 01 00 00 00 00 05 30 00 00 0C 2F
					39 01 00 00 00 00 05 2A 00 00 05 9F
					39 01 00 00 3C 00 05 2B 00 00 0C 2F
					15 01 00 00 00 00 02 B0 AC
					39 01 00 00 00 00 07 B8 3D 01 1F 01 FF 3C
					39 01 00 00 00 00 21 B9 11 00 00 89 30 80 0C 30 05 A0 00 3C 02 D0 02 D0 02 00 02 C2 00 20 05 D9 00 0A 00 0F 02 09 01 46
					39 01 00 00 00 00 21 BA 11 00 00 89 30 80 09 24 04 38 00 3C 02 1C 02 1C 02 00 02 52 00 20 05 30 00 07 00 0F 02 09 01 B2
					39 01 00 00 00 00 21 BB 11 00 00 89 30 80 06 18 02 D0 00 3C 01 68 01 68 02 00 01 E1 00 20 04 3A 00 05 00 0F 02 09 02 8B
					15 01 00 00 00 00 02 B0 55
					39 01 00 00 00 00 0D E3 01 93 E8 E8 E8 E8 E8 E8 E8 FF 00 ED
					39 01 00 00 00 00 21 EC 3F 03 05 AF 03 01 6B 03 01 6B 00 FF 80 00 80 00 80 00 80 00 ED 7E FB 79 F7 75 F2 70 00 CA 79 F3
					39 01 00 00 00 00 06 ED 6C E5 5F D8 52
					39 01 00 00 00 00 21 CC 88 0A 4B 6C FF 58 60 60 80 67 70 80 7A 74 6E 60 79 65 60 60 68 74 67 87 7A 74 6A 60 7A 7A 5C 6C
					39 01 00 00 00 00 21 CD 6C 80 80 7A 79 75 6A 68 7C 83 83 83 83 83 83 83 83 83 83 83 83 83 83 83 83 83 83 83 83 83 83 83
					39 01 00 00 00 00 21 CE 83 83 83 83 83 83 83 7A 83 83 83 83 83 7F 7F 7F 7F 7F 7F 7F 7E 7E 7E 7F 7F F4 00 06 02 01 0A E4
					39 01 00 00 00 00 21 CF EF EF EF F6 06 00 0A 81 D3 FF 4C 50 48 48 4C 50 50 4A 45 4E 4C 52 54 54 54 58 58 68 65 6B 53 5B
					39 01 00 00 00 00 21 D0 50 56 66 66 6C 68 7A 6A 80 72 6F 66 68 6A 80 80 80 80 80 80 80 80 80 80 80 80 80 80 80 80 80 80
					39 01 00 00 00 00 21 D1 80 80 80 80 80 80 80 80 80 80 80 80 80 80 80 80 80 80 7F 7F 7F 7F 7F 7E 7F 7D 7E 7F 7F 7E FB 06
					39 01 00 00 00 00 21 D2 FB F6 03 0C F4 E9 EF FB 03 01 00 0A 81 D3 FF 48 44 44 4E 53 52 50 50 4C 60 54 50 4C 50 4C 56 5A
					39 01 00 00 00 00 21 D3 62 5F 60 5D 64 60 60 60 5D 61 69 68 79 77 6B 80 80 80 7D 80 80 80 80 80 80 80 80 80 80 80 80 80
					39 01 00 00 00 00 21 D4 80 80 80 80 80 80 80 80 80 80 80 80 80 80 80 80 80 80 80 80 80 80 80 7F 7E 7F 7F 7F 7F 7F 7E 7F
					39 01 00 00 00 00 21 D5 7D 7F 7F FB 0C 0A 0A 03 03 F8 F2 0A 15 01 F4 00 0A 81 D3 FF 48 46 40 3A 42 42 4C 4C 3C 38 38 44
					39 01 00 00 00 00 21 D6 4D 54 46 4A 49 58 59 5D 42 38 3A 4A 5E 68 60 5A 68 58 70 66 56 4A 4A 5F 80 80 80 80 80 80 80 80
					39 01 00 00 00 00 21 D7 80 80 80 80 80 80 80 80 80 80 80 80 80 80 80 80 80 80 80 80 80 80 80 80 80 80 80 80 7F 7F 7E 7E
					39 01 00 00 00 00 15 D8 7F 7D 7F 7A 7C 7E 7F 7E FB F8 ED F2 06 15 F8 DC E2 F2 03 0C
					39 01 00 00 3C 00 07 55 16 29 C0 04 78 DB
				];
				qcom,mdss-dsi-on-command-state = "dsi_lp_mode";

				qcom,mdss-dsi-post-panel-on-command = [
					05 01 00 00 00 00 01 29
				];

				qcom,mdss-dsi-off-command = [
					05 01 00 00 00 00 01 28
					05 01 00 00 96 00 01 10
					];
				qcom,mdss-dsi-off-command-state = "dsi_hs_mode";

				qcom,mdss-dsi-timing-switch-command = [
					15 00 00 00 00 00 02 B0 AC
					07 00 00 00 00 00 02 11 00
					15 01 00 00 00 00 02 3D 08
				];
				qcom,mdss-dsi-timing-switch-command-state = "dsi_lp_mode";

				qcom,mdss-dsi-h-sync-pulse = <0>;
				qcom,compression-mode = "dsc";
				qcom,mdss-dsc-version = <0x11>;
				qcom,mdss-dsc-scr-version = <0x1>;
				qcom,mdss-dsc-slice-height = <60>;
				qcom,mdss-dsc-slice-width = <720>;
				qcom,mdss-dsc-slice-per-pkt = <2>;
				qcom,mdss-dsc-bit-per-component = <8>;
				qcom,mdss-dsc-bit-per-pixel = <8>;
				qcom,lm-split = <720 720>;
				qcom,mdss-dsc-encoders = <2>;
				qcom,mdss-dsc-block-prediction-enable;
				qcom,mdss-dsi-pps-command-state = "dsi_hs_mode";
			};

			timing@1 {
				qcom,partial-update-enabled = "single_roi";
				qcom,panel-roi-alignment = <1080 60 1080 60 1080 60>;
				qcom,mdss-dsi-panel-phy-timings = [00 1D 07 07 23 22 07 07 05 02 04 00 18 17];
				qcom,mdss-dsi-panel-clockrate = <903302400>;
				qcom,display-topology = <2 2 1>;
				qcom,default-topology-index = <0>;
				qcom,mdss-dsi-panel-framerate = <60>;
				qcom,mdss-dsi-panel-width = <1080>;
				qcom,mdss-dsi-panel-height = <2340>;
				qcom,mdss-dsi-h-front-porch = <188>;
				qcom,mdss-dsi-h-back-porch = <188>;
				qcom,mdss-dsi-h-pulse-width = <16>;
				qcom,mdss-dsi-h-sync-skew = <0>;
				qcom,mdss-dsi-v-back-porch = <450>;
				qcom,mdss-dsi-v-front-porch = <289>;
				qcom,mdss-dsi-v-pulse-width = <1>;
				qcom,mdss-dsi-h-left-border = <0>;
				qcom,mdss-dsi-h-right-border = <0>;
				qcom,mdss-dsi-v-top-border = <0>;
				qcom,mdss-dsi-v-bottom-border = <0>;
				qcom,mdss-mdp-transfer-time-us = <15200>;

				qcom,mdss-dsi-on-command = [
					07 01 00 00 00 00 02 21 00
					15 01 00 00 00 00 02 B0 AC
					39 01 00 00 00 00 07 F7 01 49 0C FF 7F 04
					15 01 00 00 00 00 02 B0 CA
					39 01 00 00 00 00 07 55 00 70 DF 00 70 DF
					05 01 00 00 82 00 01 11
					15 01 00 00 00 00 02 26 02
					15 01 00 00 00 00 02 3D 09
					39 01 00 00 00 00 03 53 4C 30
					15 01 00 00 00 00 02 35 00
					39 01 00 00 00 00 03 44 00 00
					39 01 00 00 00 00 05 30 00 00 0C 2F
					39 01 00 00 00 00 05 2A 00 00 05 9F
					39 01 00 00 3C 00 05 2B 00 00 0C 2F
					15 01 00 00 00 00 02 B0 AC
					39 01 00 00 00 00 07 B8 3D 01 1F 01 FF 3C
					39 01 00 00 00 00 21 B9 11 00 00 89 30 80 0C 30 05 A0 00 3C 02 D0 02 D0 02 00 02 C2 00 20 05 D9 00 0A 00 0F 02 09 01 46
					39 01 00 00 00 00 21 BA 11 00 00 89 30 80 09 24 04 38 00 3C 02 1C 02 1C 02 00 02 52 00 20 05 30 00 07 00 0F 02 09 01 B2
					39 01 00 00 00 00 21 BB 11 00 00 89 30 80 06 18 02 D0 00 3C 01 68 01 68 02 00 01 E1 00 20 04 3A 00 05 00 0F 02 09 02 8B
					15 01 00 00 00 00 02 B0 55
					39 01 00 00 00 00 0D E3 01 93 E8 E8 E8 E8 E8 E8 E8 FF 00 ED
					39 01 00 00 00 00 21 EC 3F 03 05 AF 03 01 6B 03 01 6B 00 FF 80 00 80 00 80 00 80 00 ED 7E FB 79 F7 75 F2 70 00 CA 79 F3
					39 01 00 00 00 00 06 ED 6C E5 5F D8 52
					39 01 00 00 00 00 21 CC 88 0A 4B 6C FF 58 60 60 80 67 70 80 7A 74 6E 60 79 65 60 60 68 74 67 87 7A 74 6A 60 7A 7A 5C 6C
					39 01 00 00 00 00 21 CD 6C 80 80 7A 79 75 6A 68 7C 83 83 83 83 83 83 83 83 83 83 83 83 83 83 83 83 83 83 83 83 83 83 83
					39 01 00 00 00 00 21 CE 83 83 83 83 83 83 83 7A 83 83 83 83 83 7F 7F 7F 7F 7F 7F 7F 7E 7E 7E 7F 7F F4 00 06 02 01 0A E4
					39 01 00 00 00 00 21 CF EF EF EF F6 06 00 0A 81 D3 FF 4C 50 48 48 4C 50 50 4A 45 4E 4C 52 54 54 54 58 58 68 65 6B 53 5B
					39 01 00 00 00 00 21 D0 50 56 66 66 6C 68 7A 6A 80 72 6F 66 68 6A 80 80 80 80 80 80 80 80 80 80 80 80 80 80 80 80 80 80
					39 01 00 00 00 00 21 D1 80 80 80 80 80 80 80 80 80 80 80 80 80 80 80 80 80 80 7F 7F 7F 7F 7F 7E 7F 7D 7E 7F 7F 7E FB 06
					39 01 00 00 00 00 21 D2 FB F6 03 0C F4 E9 EF FB 03 01 00 0A 81 D3 FF 48 44 44 4E 53 52 50 50 4C 60 54 50 4C 50 4C 56 5A
					39 01 00 00 00 00 21 D3 62 5F 60 5D 64 60 60 60 5D 61 69 68 79 77 6B 80 80 80 7D 80 80 80 80 80 80 80 80 80 80 80 80 80
					39 01 00 00 00 00 21 D4 80 80 80 80 80 80 80 80 80 80 80 80 80 80 80 80 80 80 80 80 80 80 80 7F 7E 7F 7F 7F 7F 7F 7E 7F
					39 01 00 00 00 00 21 D5 7D 7F 7F FB 0C 0A 0A 03 03 F8 F2 0A 15 01 F4 00 0A 81 D3 FF 48 46 40 3A 42 42 4C 4C 3C 38 38 44
					39 01 00 00 00 00 21 D6 4D 54 46 4A 49 58 59 5D 42 38 3A 4A 5E 68 60 5A 68 58 70 66 56 4A 4A 5F 80 80 80 80 80 80 80 80
					39 01 00 00 00 00 21 D7 80 80 80 80 80 80 80 80 80 80 80 80 80 80 80 80 80 80 80 80 80 80 80 80 80 80 80 80 7F 7F 7E 7E
					39 01 00 00 00 00 15 D8 7F 7D 7F 7A 7C 7E 7F 7E FB F8 ED F2 06 15 F8 DC E2 F2 03 0C
					39 01 00 00 3C 00 07 55 16 29 C0 04 78 DB
				];
				qcom,mdss-dsi-on-command-state = "dsi_lp_mode";

				qcom,mdss-dsi-post-panel-on-command = [
					05 01 00 00 00 00 01 29
				];

				qcom,mdss-dsi-off-command = [
					05 01 00 00 00 00 01 28
					05 01 00 00 96 00 01 10
				];
				qcom,mdss-dsi-timing-switch-command = [
					15 00 00 00 00 00 02 B0 AC
					07 00 00 00 00 00 02 21 00
					15 01 00 00 00 00 02 3D 09
				];

				qcom,mdss-dsi-timing-switch-command-state = "dsi_lp_mode";
				qcom,mdss-dsi-off-command-state = "dsi_lp_mode";
				qcom,compression-mode = "dsc";
				qcom,mdss-dsc-version = <0x11>;
				qcom,mdss-dsc-scr-version = <0x1>;
				qcom,mdss-dsc-slice-height = <60>;
				qcom,mdss-dsc-slice-width = <540>;
				qcom,mdss-dsc-slice-per-pkt = <2>;
				qcom,mdss-dsc-bit-per-component = <8>;
				qcom,mdss-dsc-bit-per-pixel = <8>;
				qcom,lm-split = <540 540>;
				qcom,mdss-dsc-encoders = <2>;
				qcom,mdss-dsc-block-prediction-enable;
				qcom,mdss-dsi-pps-command-state = "dsi_hs_mode";
			};

			timing@2{
				qcom,partial-update-enabled = "single_roi";
				qcom,panel-roi-alignment = <720 60 720 60 720 60>;
				qcom,mdss-dsi-panel-phy-timings = [00 1D 07 07 23 22 07 07 05 02 04 00 18 17];
				qcom,mdss-dsi-panel-clockrate = <903302400>;
				qcom,display-topology = <2 2 1>;
				qcom,default-topology-index = <0>;
				qcom,mdss-dsi-panel-framerate = <60>;
				qcom,mdss-dsi-panel-width = <720>;
				qcom,mdss-dsi-panel-height = <1560>;
				qcom,mdss-dsi-h-front-porch = <240>;
				qcom,mdss-dsi-h-back-porch = <240>;
				qcom,mdss-dsi-h-pulse-width = <48>;
				qcom,mdss-dsi-h-sync-skew = <0>;
				qcom,mdss-dsi-v-back-porch = <728>;
				qcom,mdss-dsi-v-front-porch = <728>;
				qcom,mdss-dsi-v-pulse-width = <4>;
				qcom,mdss-dsi-h-left-border = <0>;
				qcom,mdss-dsi-h-right-border = <0>;
				qcom,mdss-dsi-v-top-border = <0>;
				qcom,mdss-dsi-v-bottom-border = <0>;
				qcom,mdss-mdp-transfer-time-us = <15200>;

				qcom,mdss-dsi-on-command = [
					07 01 00 00 00 00 02 31 00
					15 01 00 00 00 00 02 B0 AC
					39 01 00 00 00 00 07 F7 01 49 0C FF 7F 04
					15 01 00 00 00 00 02 B0 CA
					39 01 00 00 00 00 07 55 00 70 DF 00 70 DF
					05 01 00 00 82 00 01 11
					15 01 00 00 00 00 02 26 02
					15 01 00 00 00 00 02 3D 0B
					39 01 00 00 00 00 03 53 4C 30
					15 01 00 00 00 00 02 35 00
					39 01 00 00 00 00 03 44 00 00
					39 01 00 00 00 00 05 30 00 00 0C 2F
					39 01 00 00 00 00 05 2A 00 00 05 9F
					39 01 00 00 3C 00 05 2B 00 00 0C 2F
					15 01 00 00 00 00 02 B0 AC
					39 01 00 00 00 00 07 B8 3D 01 1F 01 FF 3C
					39 01 00 00 00 00 21 B9 11 00 00 89 30 80 0C 30 05 A0 00 3C 02 D0 02 D0 02 00 02 C2 00 20 05 D9 00 0A 00 0F 02 09 01 46
					39 01 00 00 00 00 21 BA 11 00 00 89 30 80 09 24 04 38 00 3C 02 1C 02 1C 02 00 02 52 00 20 05 30 00 07 00 0F 02 09 01 B2
					39 01 00 00 00 00 21 BB 11 00 00 89 30 80 06 18 02 D0 00 3C 01 68 01 68 02 00 01 E1 00 20 04 3A 00 05 00 0F 02 09 02 8B
					15 01 00 00 00 00 02 B0 55
					39 01 00 00 00 00 0D E3 01 93 E8 E8 E8 E8 E8 E8 E8 FF 00 ED
					39 01 00 00 00 00 21 EC 3F 03 05 AF 03 01 6B 03 01 6B 00 FF 80 00 80 00 80 00 80 00 ED 7E FB 79 F7 75 F2 70 00 CA 79 F3
					39 01 00 00 00 00 06 ED 6C E5 5F D8 52
					39 01 00 00 00 00 21 CC 88 0A 4B 6C FF 58 60 60 80 67 70 80 7A 74 6E 60 79 65 60 60 68 74 67 87 7A 74 6A 60 7A 7A 5C 6C
					39 01 00 00 00 00 21 CD 6C 80 80 7A 79 75 6A 68 7C 83 83 83 83 83 83 83 83 83 83 83 83 83 83 83 83 83 83 83 83 83 83 83
					39 01 00 00 00 00 21 CE 83 83 83 83 83 83 83 7A 83 83 83 83 83 7F 7F 7F 7F 7F 7F 7F 7E 7E 7E 7F 7F F4 00 06 02 01 0A E4
					39 01 00 00 00 00 21 CF EF EF EF F6 06 00 0A 81 D3 FF 4C 50 48 48 4C 50 50 4A 45 4E 4C 52 54 54 54 58 58 68 65 6B 53 5B
					39 01 00 00 00 00 21 D0 50 56 66 66 6C 68 7A 6A 80 72 6F 66 68 6A 80 80 80 80 80 80 80 80 80 80 80 80 80 80 80 80 80 80
					39 01 00 00 00 00 21 D1 80 80 80 80 80 80 80 80 80 80 80 80 80 80 80 80 80 80 7F 7F 7F 7F 7F 7E 7F 7D 7E 7F 7F 7E FB 06
					39 01 00 00 00 00 21 D2 FB F6 03 0C F4 E9 EF FB 03 01 00 0A 81 D3 FF 48 44 44 4E 53 52 50 50 4C 60 54 50 4C 50 4C 56 5A
					39 01 00 00 00 00 21 D3 62 5F 60 5D 64 60 60 60 5D 61 69 68 79 77 6B 80 80 80 7D 80 80 80 80 80 80 80 80 80 80 80 80 80
					39 01 00 00 00 00 21 D4 80 80 80 80 80 80 80 80 80 80 80 80 80 80 80 80 80 80 80 80 80 80 80 7F 7E 7F 7F 7F 7F 7F 7E 7F
					39 01 00 00 00 00 21 D5 7D 7F 7F FB 0C 0A 0A 03 03 F8 F2 0A 15 01 F4 00 0A 81 D3 FF 48 46 40 3A 42 42 4C 4C 3C 38 38 44
					39 01 00 00 00 00 21 D6 4D 54 46 4A 49 58 59 5D 42 38 3A 4A 5E 68 60 5A 68 58 70 66 56 4A 4A 5F 80 80 80 80 80 80 80 80
					39 01 00 00 00 00 21 D7 80 80 80 80 80 80 80 80 80 80 80 80 80 80 80 80 80 80 80 80 80 80 80 80 80 80 80 80 7F 7F 7E 7E
					39 01 00 00 00 00 15 D8 7F 7D 7F 7A 7C 7E 7F 7E FB F8 ED F2 06 15 F8 DC E2 F2 03 0C
					39 01 00 00 3C 00 07 55 16 29 C0 04 78 DB
				];
				qcom,mdss-dsi-on-command-state = "dsi_lp_mode";

				qcom,mdss-dsi-post-panel-on-command = [
					05 01 00 00 00 00 01 29
				];

				qcom,mdss-dsi-off-command = [
					05 01 00 00 00 00 01 28
					05 01 00 00 96 00 01 10
				];
				qcom,mdss-dsi-timing-switch-command = [
					15 00 00 00 00 00 02 B0 AC
					07 00 00 00 00 00 02 31 00
					15 01 00 00 00 00 02 3D 0B
				];
				qcom,mdss-dsi-timing-switch-command-state = "dsi_lp_mode";

				qcom,compression-mode = "dsc";
				qcom,mdss-dsc-version = <0x11>;
				qcom,mdss-dsc-scr-version = <0x1>;
				qcom,mdss-dsc-slice-height = <60>;
				qcom,mdss-dsc-slice-width = <360>;
				qcom,mdss-dsc-slice-per-pkt = <2>;
				qcom,mdss-dsc-bit-per-component = <8>;
				qcom,mdss-dsc-bit-per-pixel = <8>;
				qcom,lm-split = <360 360>;
				qcom,mdss-dsc-encoders = <2>;
				qcom,mdss-dsc-block-prediction-enable;
				qcom,mdss-dsi-pps-command-state = "dsi_hs_mode";
			};
			timing_30Hz@3{
				qcom,partial-update-enabled = "single_roi";
				qcom,panel-roi-alignment = <1440 60 1440 60 1440 60>;
				qcom,mdss-dsi-panel-phy-timings = [00 1D 07 07 23 22 07 07 05 02 04 00 18 17];
				qcom,mdss-dsi-panel-clockrate = <903302400>;
				qcom,display-topology = <2 2 1>;
				qcom,default-topology-index = <0>;
				qcom,mdss-dsi-panel-framerate = <60>;
				qcom,mdss-dsi-panel-width = <1440>;
				qcom,mdss-dsi-panel-height = <3120>;
				qcom,mdss-dsi-h-front-porch = <168>;
				qcom,mdss-dsi-h-back-porch = <88>;
				qcom,mdss-dsi-h-pulse-width = <4>;
				qcom,mdss-dsi-h-sync-skew = <0>;
				qcom,mdss-dsi-v-back-porch = <10>;
				qcom,mdss-dsi-v-front-porch = <9>;
				qcom,mdss-dsi-v-pulse-width = <1>;
				qcom,mdss-dsi-h-left-border = <0>;
				qcom,mdss-dsi-h-right-border = <0>;
				qcom,mdss-dsi-v-top-border = <0>;
				qcom,mdss-dsi-v-bottom-border = <0>;
				qcom,mdss-mdp-transfer-time-us = <15200>;
				lge,mdss-dsi-panel-framerate-div = <2>;

				qcom,mdss-dsi-on-command = [
					07 01 00 00 00 00 02 11 00
					15 01 00 00 00 00 02 B0 AC
					39 01 00 00 00 00 07 F7 01 49 0C FF 7F 04
					15 01 00 00 00 00 02 B0 CA
					39 01 00 00 00 00 07 55 00 70 DF 00 70 DF
					05 01 00 00 82 00 01 11
					15 01 00 00 00 00 02 26 02
					15 01 00 00 00 00 02 3D 08
					39 01 00 00 00 00 03 53 4C 30
					15 01 00 00 00 00 02 35 00
					39 01 00 00 00 00 03 44 00 00
					39 01 00 00 00 00 05 30 00 00 0C 2F
					39 01 00 00 00 00 05 2A 00 00 05 9F
					39 01 00 00 3C 00 05 2B 00 00 0C 2F
					15 01 00 00 00 00 02 B0 AC
					39 01 00 00 00 00 07 B8 3D 01 1F 01 FF 3C
					39 01 00 00 00 00 21 B9 11 00 00 89 30 80 0C 30 05 A0 00 3C 02 D0 02 D0 02 00 02 C2 00 20 05 D9 00 0A 00 0F 02 09 01 46
					39 01 00 00 00 00 21 BA 11 00 00 89 30 80 09 24 04 38 00 3C 02 1C 02 1C 02 00 02 52 00 20 05 30 00 07 00 0F 02 09 01 B2
					39 01 00 00 00 00 21 BB 11 00 00 89 30 80 06 18 02 D0 00 3C 01 68 01 68 02 00 01 E1 00 20 04 3A 00 05 00 0F 02 09 02 8B
					15 01 00 00 00 00 02 B0 55
					39 01 00 00 00 00 0D E3 01 93 E8 E8 E8 E8 E8 E8 E8 FF 00 ED
					39 01 00 00 00 00 21 EC 3F 03 05 AF 03 01 6B 03 01 6B 00 FF 80 00 80 00 80 00 80 00 ED 7E FB 79 F7 75 F2 70 00 CA 79 F3
					39 01 00 00 00 00 06 ED 6C E5 5F D8 52
					39 01 00 00 00 00 21 CC 88 0A 4B 6C FF 58 60 60 80 67 70 80 7A 74 6E 60 79 65 60 60 68 74 67 87 7A 74 6A 60 7A 7A 5C 6C
					39 01 00 00 00 00 21 CD 6C 80 80 7A 79 75 6A 68 7C 83 83 83 83 83 83 83 83 83 83 83 83 83 83 83 83 83 83 83 83 83 83 83
					39 01 00 00 00 00 21 CE 83 83 83 83 83 83 83 7A 83 83 83 83 83 7F 7F 7F 7F 7F 7F 7F 7E 7E 7E 7F 7F F4 00 06 02 01 0A E4
					39 01 00 00 00 00 21 CF EF EF EF F6 06 00 0A 81 D3 FF 4C 50 48 48 4C 50 50 4A 45 4E 4C 52 54 54 54 58 58 68 65 6B 53 5B
					39 01 00 00 00 00 21 D0 50 56 66 66 6C 68 7A 6A 80 72 6F 66 68 6A 80 80 80 80 80 80 80 80 80 80 80 80 80 80 80 80 80 80
					39 01 00 00 00 00 21 D1 80 80 80 80 80 80 80 80 80 80 80 80 80 80 80 80 80 80 7F 7F 7F 7F 7F 7E 7F 7D 7E 7F 7F 7E FB 06
					39 01 00 00 00 00 21 D2 FB F6 03 0C F4 E9 EF FB 03 01 00 0A 81 D3 FF 48 44 44 4E 53 52 50 50 4C 60 54 50 4C 50 4C 56 5A
					39 01 00 00 00 00 21 D3 62 5F 60 5D 64 60 60 60 5D 61 69 68 79 77 6B 80 80 80 7D 80 80 80 80 80 80 80 80 80 80 80 80 80
					39 01 00 00 00 00 21 D4 80 80 80 80 80 80 80 80 80 80 80 80 80 80 80 80 80 80 80 80 80 80 80 7F 7E 7F 7F 7F 7F 7F 7E 7F
					39 01 00 00 00 00 21 D5 7D 7F 7F FB 0C 0A 0A 03 03 F8 F2 0A 15 01 F4 00 0A 81 D3 FF 48 46 40 3A 42 42 4C 4C 3C 38 38 44
					39 01 00 00 00 00 21 D6 4D 54 46 4A 49 58 59 5D 42 38 3A 4A 5E 68 60 5A 68 58 70 66 56 4A 4A 5F 80 80 80 80 80 80 80 80
					39 01 00 00 00 00 21 D7 80 80 80 80 80 80 80 80 80 80 80 80 80 80 80 80 80 80 80 80 80 80 80 80 80 80 80 80 7F 7F 7E 7E
					39 01 00 00 00 00 15 D8 7F 7D 7F 7A 7C 7E 7F 7E FB F8 ED F2 06 15 F8 DC E2 F2 03 0C
					39 01 00 00 3C 00 07 55 16 29 C0 04 78 DB
				];
				qcom,mdss-dsi-on-command-state = "dsi_lp_mode";

				qcom,mdss-dsi-post-panel-on-command = [
					05 01 00 00 00 00 01 29
				];

				qcom,mdss-dsi-off-command = [
					05 01 00 00 00 00 01 28
					05 01 00 00 96 00 01 10
					];
				qcom,mdss-dsi-off-command-state = "dsi_hs_mode";

				qcom,mdss-dsi-timing-switch-command = [
					15 00 00 00 00 00 02 B0 AC
					07 00 00 00 00 00 02 11 00
					15 01 00 00 00 00 02 3D 08
				];
				qcom,mdss-dsi-timing-switch-command-state = "dsi_lp_mode";

				qcom,mdss-dsi-h-sync-pulse = <0>;
				qcom,compression-mode = "dsc";
				qcom,mdss-dsc-version = <0x11>;
				qcom,mdss-dsc-scr-version = <0x1>;
				qcom,mdss-dsc-slice-height = <60>;
				qcom,mdss-dsc-slice-width = <720>;
				qcom,mdss-dsc-slice-per-pkt = <2>;
				qcom,mdss-dsc-bit-per-component = <8>;
				qcom,mdss-dsc-bit-per-pixel = <8>;
				qcom,lm-split = <720 720>;
				qcom,mdss-dsc-encoders = <2>;
				qcom,mdss-dsc-block-prediction-enable;
				qcom,mdss-dsi-pps-command-state = "dsi_hs_mode";
			};

			timing_30Hz@4 {
				qcom,partial-update-enabled = "single_roi";
				qcom,panel-roi-alignment = <1080 60 1080 60 1080 60>;
				qcom,mdss-dsi-panel-phy-timings = [00 1D 07 07 23 22 07 07 05 02 04 00 18 17];
				qcom,mdss-dsi-panel-clockrate = <903302400>;
				qcom,display-topology = <2 2 1>;
				qcom,default-topology-index = <0>;
				qcom,mdss-dsi-panel-framerate = <60>;
				qcom,mdss-dsi-panel-width = <1080>;
				qcom,mdss-dsi-panel-height = <2340>;
				qcom,mdss-dsi-h-front-porch = <188>;
				qcom,mdss-dsi-h-back-porch = <188>;
				qcom,mdss-dsi-h-pulse-width = <16>;
				qcom,mdss-dsi-h-sync-skew = <0>;
				qcom,mdss-dsi-v-back-porch = <450>;
				qcom,mdss-dsi-v-front-porch = <289>;
				qcom,mdss-dsi-v-pulse-width = <1>;
				qcom,mdss-dsi-h-left-border = <0>;
				qcom,mdss-dsi-h-right-border = <0>;
				qcom,mdss-dsi-v-top-border = <0>;
				qcom,mdss-dsi-v-bottom-border = <0>;
				qcom,mdss-mdp-transfer-time-us = <15200>;
				lge,mdss-dsi-panel-framerate-div = <2>;

				qcom,mdss-dsi-on-command = [
					07 01 00 00 00 00 02 21 00
					15 01 00 00 00 00 02 B0 AC
					39 01 00 00 00 00 07 F7 01 49 0C FF 7F 04
					15 01 00 00 00 00 02 B0 CA
					39 01 00 00 00 00 07 55 00 70 DF 00 70 DF
					05 01 00 00 82 00 01 11
					15 01 00 00 00 00 02 26 02
					15 01 00 00 00 00 02 3D 09
					39 01 00 00 00 00 03 53 4C 30
					15 01 00 00 00 00 02 35 00
					39 01 00 00 00 00 03 44 00 00
					39 01 00 00 00 00 05 30 00 00 0C 2F
					39 01 00 00 00 00 05 2A 00 00 05 9F
					39 01 00 00 3C 00 05 2B 00 00 0C 2F
					15 01 00 00 00 00 02 B0 AC
					39 01 00 00 00 00 07 B8 3D 01 1F 01 FF 3C
					39 01 00 00 00 00 21 B9 11 00 00 89 30 80 0C 30 05 A0 00 3C 02 D0 02 D0 02 00 02 C2 00 20 05 D9 00 0A 00 0F 02 09 01 46
					39 01 00 00 00 00 21 BA 11 00 00 89 30 80 09 24 04 38 00 3C 02 1C 02 1C 02 00 02 52 00 20 05 30 00 07 00 0F 02 09 01 B2
					39 01 00 00 00 00 21 BB 11 00 00 89 30 80 06 18 02 D0 00 3C 01 68 01 68 02 00 01 E1 00 20 04 3A 00 05 00 0F 02 09 02 8B
					15 01 00 00 00 00 02 B0 55
					39 01 00 00 00 00 0D E3 01 93 E8 E8 E8 E8 E8 E8 E8 FF 00 ED
					39 01 00 00 00 00 21 EC 3F 03 05 AF 03 01 6B 03 01 6B 00 FF 80 00 80 00 80 00 80 00 ED 7E FB 79 F7 75 F2 70 00 CA 79 F3
					39 01 00 00 00 00 06 ED 6C E5 5F D8 52
					39 01 00 00 00 00 21 CC 88 0A 4B 6C FF 58 60 60 80 67 70 80 7A 74 6E 60 79 65 60 60 68 74 67 87 7A 74 6A 60 7A 7A 5C 6C
					39 01 00 00 00 00 21 CD 6C 80 80 7A 79 75 6A 68 7C 83 83 83 83 83 83 83 83 83 83 83 83 83 83 83 83 83 83 83 83 83 83 83
					39 01 00 00 00 00 21 CE 83 83 83 83 83 83 83 7A 83 83 83 83 83 7F 7F 7F 7F 7F 7F 7F 7E 7E 7E 7F 7F F4 00 06 02 01 0A E4
					39 01 00 00 00 00 21 CF EF EF EF F6 06 00 0A 81 D3 FF 4C 50 48 48 4C 50 50 4A 45 4E 4C 52 54 54 54 58 58 68 65 6B 53 5B
					39 01 00 00 00 00 21 D0 50 56 66 66 6C 68 7A 6A 80 72 6F 66 68 6A 80 80 80 80 80 80 80 80 80 80 80 80 80 80 80 80 80 80
					39 01 00 00 00 00 21 D1 80 80 80 80 80 80 80 80 80 80 80 80 80 80 80 80 80 80 7F 7F 7F 7F 7F 7E 7F 7D 7E 7F 7F 7E FB 06
					39 01 00 00 00 00 21 D2 FB F6 03 0C F4 E9 EF FB 03 01 00 0A 81 D3 FF 48 44 44 4E 53 52 50 50 4C 60 54 50 4C 50 4C 56 5A
					39 01 00 00 00 00 21 D3 62 5F 60 5D 64 60 60 60 5D 61 69 68 79 77 6B 80 80 80 7D 80 80 80 80 80 80 80 80 80 80 80 80 80
					39 01 00 00 00 00 21 D4 80 80 80 80 80 80 80 80 80 80 80 80 80 80 80 80 80 80 80 80 80 80 80 7F 7E 7F 7F 7F 7F 7F 7E 7F
					39 01 00 00 00 00 21 D5 7D 7F 7F FB 0C 0A 0A 03 03 F8 F2 0A 15 01 F4 00 0A 81 D3 FF 48 46 40 3A 42 42 4C 4C 3C 38 38 44
					39 01 00 00 00 00 21 D6 4D 54 46 4A 49 58 59 5D 42 38 3A 4A 5E 68 60 5A 68 58 70 66 56 4A 4A 5F 80 80 80 80 80 80 80 80
					39 01 00 00 00 00 21 D7 80 80 80 80 80 80 80 80 80 80 80 80 80 80 80 80 80 80 80 80 80 80 80 80 80 80 80 80 7F 7F 7E 7E
					39 01 00 00 00 00 15 D8 7F 7D 7F 7A 7C 7E 7F 7E FB F8 ED F2 06 15 F8 DC E2 F2 03 0C
					39 01 00 00 3C 00 07 55 16 29 C0 04 78 DB
				];
				qcom,mdss-dsi-on-command-state = "dsi_lp_mode";

				qcom,mdss-dsi-post-panel-on-command = [
					05 01 00 00 00 00 01 29
				];

				qcom,mdss-dsi-off-command = [
					05 01 00 00 00 00 01 28
					05 01 00 00 96 00 01 10
				];
				qcom,mdss-dsi-timing-switch-command = [
					15 00 00 00 00 00 02 B0 AC
					07 00 00 00 00 00 02 21 00
					15 01 00 00 00 00 02 3D 09
				];

				qcom,mdss-dsi-timing-switch-command-state = "dsi_lp_mode";
				qcom,mdss-dsi-off-command-state = "dsi_lp_mode";
				qcom,compression-mode = "dsc";
				qcom,mdss-dsc-version = <0x11>;
				qcom,mdss-dsc-scr-version = <0x1>;
				qcom,mdss-dsc-slice-height = <60>;
				qcom,mdss-dsc-slice-width = <540>;
				qcom,mdss-dsc-slice-per-pkt = <2>;
				qcom,mdss-dsc-bit-per-component = <8>;
				qcom,mdss-dsc-bit-per-pixel = <8>;
				qcom,lm-split = <540 540>;
				qcom,mdss-dsc-encoders = <2>;
				qcom,mdss-dsc-block-prediction-enable;
				qcom,mdss-dsi-pps-command-state = "dsi_hs_mode";
			};

			timing_30Hz@5{
				qcom,partial-update-enabled = "single_roi";
				qcom,panel-roi-alignment = <720 60 720 60 720 60>;
				qcom,mdss-dsi-panel-phy-timings = [00 1D 07 07 23 22 07 07 05 02 04 00 18 17];
				qcom,mdss-dsi-panel-clockrate = <903302400>;
				qcom,display-topology = <2 2 1>;
				qcom,default-topology-index = <0>;
				qcom,mdss-dsi-panel-framerate = <60>;
				qcom,mdss-dsi-panel-width = <720>;
				qcom,mdss-dsi-panel-height = <1560>;
				qcom,mdss-dsi-h-front-porch = <240>;
				qcom,mdss-dsi-h-back-porch = <240>;
				qcom,mdss-dsi-h-pulse-width = <48>;
				qcom,mdss-dsi-h-sync-skew = <0>;
				qcom,mdss-dsi-v-back-porch = <728>;
				qcom,mdss-dsi-v-front-porch = <728>;
				qcom,mdss-dsi-v-pulse-width = <4>;
				qcom,mdss-dsi-h-left-border = <0>;
				qcom,mdss-dsi-h-right-border = <0>;
				qcom,mdss-dsi-v-top-border = <0>;
				qcom,mdss-dsi-v-bottom-border = <0>;
				qcom,mdss-mdp-transfer-time-us = <15200>;
				lge,mdss-dsi-panel-framerate-div = <2>;

				qcom,mdss-dsi-on-command = [
					07 01 00 00 00 00 02 31 00
					15 01 00 00 00 00 02 B0 AC
					39 01 00 00 00 00 07 F7 01 49 0C FF 7F 04
					15 01 00 00 00 00 02 B0 CA
					39 01 00 00 00 00 07 55 00 70 DF 00 70 DF
					05 01 00 00 82 00 01 11
					15 01 00 00 00 00 02 26 02
					15 01 00 00 00 00 02 3D 0B
					39 01 00 00 00 00 03 53 4C 30
					15 01 00 00 00 00 02 35 00
					39 01 00 00 00 00 03 44 00 00
					39 01 00 00 00 00 05 30 00 00 0C 2F
					39 01 00 00 00 00 05 2A 00 00 05 9F
					39 01 00 00 3C 00 05 2B 00 00 0C 2F
					15 01 00 00 00 00 02 B0 AC
					39 01 00 00 00 00 07 B8 3D 01 1F 01 FF 3C
					39 01 00 00 00 00 21 B9 11 00 00 89 30 80 0C 30 05 A0 00 3C 02 D0 02 D0 02 00 02 C2 00 20 05 D9 00 0A 00 0F 02 09 01 46
					39 01 00 00 00 00 21 BA 11 00 00 89 30 80 09 24 04 38 00 3C 02 1C 02 1C 02 00 02 52 00 20 05 30 00 07 00 0F 02 09 01 B2
					39 01 00 00 00 00 21 BB 11 00 00 89 30 80 06 18 02 D0 00 3C 01 68 01 68 02 00 01 E1 00 20 04 3A 00 05 00 0F 02 09 02 8B
					15 01 00 00 00 00 02 B0 55
					39 01 00 00 00 00 0D E3 01 93 E8 E8 E8 E8 E8 E8 E8 FF 00 ED
					39 01 00 00 00 00 21 EC 3F 03 05 AF 03 01 6B 03 01 6B 00 FF 80 00 80 00 80 00 80 00 ED 7E FB 79 F7 75 F2 70 00 CA 79 F3
					39 01 00 00 00 00 06 ED 6C E5 5F D8 52
					39 01 00 00 00 00 21 CC 88 0A 4B 6C FF 58 60 60 80 67 70 80 7A 74 6E 60 79 65 60 60 68 74 67 87 7A 74 6A 60 7A 7A 5C 6C
					39 01 00 00 00 00 21 CD 6C 80 80 7A 79 75 6A 68 7C 83 83 83 83 83 83 83 83 83 83 83 83 83 83 83 83 83 83 83 83 83 83 83
					39 01 00 00 00 00 21 CE 83 83 83 83 83 83 83 7A 83 83 83 83 83 7F 7F 7F 7F 7F 7F 7F 7E 7E 7E 7F 7F F4 00 06 02 01 0A E4
					39 01 00 00 00 00 21 CF EF EF EF F6 06 00 0A 81 D3 FF 4C 50 48 48 4C 50 50 4A 45 4E 4C 52 54 54 54 58 58 68 65 6B 53 5B
					39 01 00 00 00 00 21 D0 50 56 66 66 6C 68 7A 6A 80 72 6F 66 68 6A 80 80 80 80 80 80 80 80 80 80 80 80 80 80 80 80 80 80
					39 01 00 00 00 00 21 D1 80 80 80 80 80 80 80 80 80 80 80 80 80 80 80 80 80 80 7F 7F 7F 7F 7F 7E 7F 7D 7E 7F 7F 7E FB 06
					39 01 00 00 00 00 21 D2 FB F6 03 0C F4 E9 EF FB 03 01 00 0A 81 D3 FF 48 44 44 4E 53 52 50 50 4C 60 54 50 4C 50 4C 56 5A
					39 01 00 00 00 00 21 D3 62 5F 60 5D 64 60 60 60 5D 61 69 68 79 77 6B 80 80 80 7D 80 80 80 80 80 80 80 80 80 80 80 80 80
					39 01 00 00 00 00 21 D4 80 80 80 80 80 80 80 80 80 80 80 80 80 80 80 80 80 80 80 80 80 80 80 7F 7E 7F 7F 7F 7F 7F 7E 7F
					39 01 00 00 00 00 21 D5 7D 7F 7F FB 0C 0A 0A 03 03 F8 F2 0A 15 01 F4 00 0A 81 D3 FF 48 46 40 3A 42 42 4C 4C 3C 38 38 44
					39 01 00 00 00 00 21 D6 4D 54 46 4A 49 58 59 5D 42 38 3A 4A 5E 68 60 5A 68 58 70 66 56 4A 4A 5F 80 80 80 80 80 80 80 80
					39 01 00 00 00 00 21 D7 80 80 80 80 80 80 80 80 80 80 80 80 80 80 80 80 80 80 80 80 80 80 80 80 80 80 80 80 7F 7F 7E 7E
					39 01 00 00 00 00 15 D8 7F 7D 7F 7A 7C 7E 7F 7E FB F8 ED F2 06 15 F8 DC E2 F2 03 0C
					39 01 00 00 3C 00 07 55 16 29 C0 04 78 DB
				];
				qcom,mdss-dsi-on-command-state = "dsi_lp_mode";

				qcom,mdss-dsi-post-panel-on-command = [
					05 01 00 00 00 00 01 29
				];

				qcom,mdss-dsi-off-command = [
					05 01 00 00 00 00 01 28
					05 01 00 00 96 00 01 10
				];
				qcom,mdss-dsi-timing-switch-command = [
					15 00 00 00 00 00 02 B0 AC
					07 00 00 00 00 00 02 31 00
					15 01 00 00 00 00 02 3D 0B
				];
				qcom,mdss-dsi-timing-switch-command-state = "dsi_lp_mode";

				qcom,compression-mode = "dsc";
				qcom,mdss-dsc-version = <0x11>;
				qcom,mdss-dsc-scr-version = <0x1>;
				qcom,mdss-dsc-slice-height = <60>;
				qcom,mdss-dsc-slice-width = <360>;
				qcom,mdss-dsc-slice-per-pkt = <2>;
				qcom,mdss-dsc-bit-per-component = <8>;
				qcom,mdss-dsc-bit-per-pixel = <8>;
				qcom,lm-split = <360 360>;
				qcom,mdss-dsc-encoders = <2>;
				qcom,mdss-dsc-block-prediction-enable;
				qcom,mdss-dsi-pps-command-state = "dsi_hs_mode";
			};
		};
	};
};
/*
&spmi_bus {
	qcom,pmi8998@3 {
		labibb: qpnp-labibb-regulator {
			status = "disabled";
		};
	};
};
*/
&mdss_dsi1 {
	status = "disabled";
};
